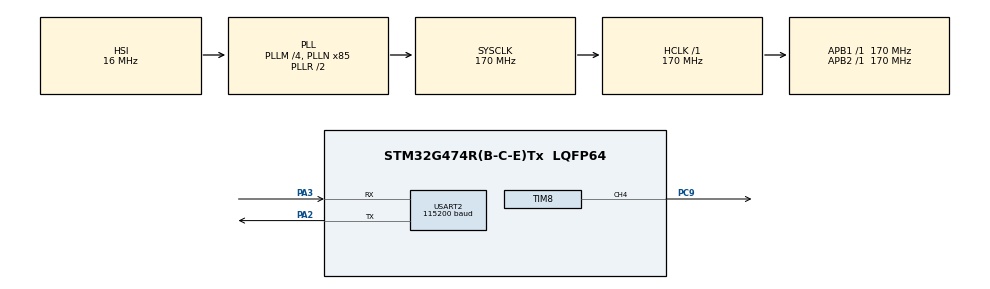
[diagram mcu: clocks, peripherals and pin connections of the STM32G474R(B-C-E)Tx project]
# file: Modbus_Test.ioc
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Dma.Request0=USART2_TX
Dma.USART2_TX.0.Direction=DMA_MEMORY_TO_PERIPH
Dma.USART2_TX.0.EventEnable=DISABLE
Dma.USART2_TX.0.Instance=DMA1_Channel1
Dma.USART2_TX.0.MemDataAlignment=DMA_MDATAALIGN_BYTE
Dma.USART2_TX.0.MemInc=DMA_MINC_ENABLE
Dma.USART2_TX.0.Mode=DMA_NORMAL
Dma.USART2_TX.0.PeriphDataAlignment=DMA_PDATAALIGN_BYTE
Dma.USART2_TX.0.PeriphInc=DMA_PINC_DISABLE
Dma.USART2_TX.0.Polarity=HAL_DMAMUX_REQ_GEN_RISING
Dma.USART2_TX.0.Priority=DMA_PRIORITY_LOW
Dma.USART2_TX.0.RequestNumber=1
Dma.USART2_TX.0.SignalID=NONE
Dma.USART2_TX.0.SyncEnable=DISABLE
Dma.USART2_TX.0.SyncPolarity=HAL_DMAMUX_SYNC_NO_EVENT
Dma.USART2_TX.0.SyncRequestNumber=1
Dma.USART2_TX.0.SyncSignalID=NONE
Mcu.Family=STM32G4
Mcu.Name=STM32G474R(B-C-E)Tx
Mcu.Package=LQFP64
NVIC.DMA1_Channel1_IRQn=true\:0\:0\:false\:false\:true\:false\:true\:true
NVIC.PriorityGroup=NVIC_PRIORITYGROUP_4
NVIC.TIM1_UP_TIM16_IRQn=true\:0\:0\:false\:false\:true\:true\:true\:true
NVIC.USART2_IRQn=true\:0\:0\:false\:false\:true\:true\:true\:true
PA13.GPIO_Label=T_SWDIO
PA13.Signal=SYS_JTMS-SWDIO
PA14.GPIO_Label=T_SWCLK
PA14.Signal=SYS_JTCK-SWCLK
PA2.Mode=Asynchronous
PA2.Signal=USART2_TX
PA3.Mode=Asynchronous
PA3.Signal=USART2_RX
PB3.GPIO_Label=T_SWO
PB3.Signal=SYS_JTDO-SWO
PC14-OSC32_IN.GPIO_Label=RCC_OSC32_IN
PC14-OSC32_IN.Signal=RCC_OSC32_IN
PC15-OSC32_OUT.GPIO_Label=RCC_OSC32_OUT
PC15-OSC32_OUT.Signal=RCC_OSC32_OUT
PC9.Signal=S_TIM8_CH4
PF0-OSC_IN.GPIO_Label=RCC_OSC_IN
PF0-OSC_IN.Signal=RCC_OSC_IN
PF1-OSC_OUT.GPIO_Label=RCC_OSC_OUT
PF1-OSC_OUT.Signal=RCC_OSC_OUT
ProjectManager.HeapSize=0x200
ProjectManager.StackSize=0x400
ProjectManager.TargetToolchain=STM32CubeIDE
RCC.ADC12Freq_Value=170000000
RCC.ADC345Freq_Value=170000000
RCC.AHBFreq_Value=170000000
RCC.APB1Freq_Value=170000000
RCC.APB1TimFreq_Value=170000000
RCC.APB2Freq_Value=170000000
RCC.APB2TimFreq_Value=170000000
RCC.CortexFreq_Value=170000000
RCC.EXTERNAL_CLOCK_VALUE=12288000
RCC.HCLKFreq_Value=170000000
RCC.HSE_VALUE=24000000
RCC.HSI48_VALUE=48000000
RCC.HSI_VALUE=16000000
RCC.LSE_VALUE=32768
RCC.PLLM=RCC_PLLM_DIV4
RCC.PLLN=85
RCC.RTCClockSelection=RCC_RTCCLKSOURCE_LSE
RCC.SYSCLKFreq_VALUE=170000000
RCC.SYSCLKSource=RCC_SYSCLKSOURCE_PLLCLK
RCC.USBFreq_Value=170000000
RCC.VCOOutputFreq_Value=340000000
SH.S_TIM8_CH4.0=TIM8_CH4,PWM Generation4 CH4
TIM16.Channel=TIM_CHANNEL_1
TIM16.OCMode_1=TIM_OCMODE_ACTIVE
TIM16.PeriodNoDither=335
TIM16.Prescaler=169
TIM16.PulseNoDither_1=239
TIM8.Channel-PWM\ Generation4\ CH4=TIM_CHANNEL_4
USART2.BaudRate=115200
USART2.Parity=PARITY_EVEN
USART2.VirtualMode-Asynchronous=VM_ASYNC
USART2.WordLength=WORDLENGTH_9B
VP_SYS_VS_DBSignals.Mode=DisableDeadBatterySignals
VP_TIM16_VS_ClockSourceINT.Mode=Enable_Timer
VP_TIM16_VS_OPM.Mode=OPM_bit
VP_TIM16_VS_no_output1.Mode=Output Compare1 No Output
VP_TIM8_VS_ClockSourceINT.Mode=Internal
board=NUCLEO-G474RE

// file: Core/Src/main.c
/* USER CODE BEGIN Header */
/**
  ******************************************************************************
  * @file           : main.c
  * @brief          : Main program body
  ******************************************************************************
  * @attention
  *
  * Copyright (c) 2025 STMicroelectronics.
  * All rights reserved.
  *
  * This software is licensed under terms that can be found in the LICENSE file
  * in the root directory of this software component.
  * If no LICENSE file comes with this software, it is provided AS-IS.
  *
  ******************************************************************************
  */
/* USER CODE END Header */
#include "main.h"

/* USER CODE BEGIN Includes */
#include "ModBusRTU.h"
/* USER CODE END Includes */

TIM_HandleTypeDef htim8;
TIM_HandleTypeDef htim16;

UART_HandleTypeDef huart2;
DMA_HandleTypeDef hdma_usart2_tx;

/* USER CODE BEGIN PV */
ModbusHandleTypedef hmodbus;
u16u8_t registerFrame[200];
float R_goal;
float theta_goal;
uint8_t status_Base ;
uint8_t status_moving ;
uint8_t A ;
/* USER CODE END PV */

void SystemClock_Config(void);
static void MX_GPIO_Init(void);
static void MX_DMA_Init(void);
static void MX_TIM16_Init(void);
static void MX_USART2_UART_Init(void);
static void MX_TIM8_Init(void);

int main(void)
{

  /* MCU Configuration--------------------------------------------------------*/

  /* Reset of all peripherals, Initializes the Flash interface and the Systick. */
  HAL_Init();

  /* Configure the system clock */
  SystemClock_Config();

  /* Initialize all configured peripherals */
  MX_GPIO_Init();
  MX_DMA_Init();
  MX_TIM16_Init();
  MX_USART2_UART_Init();
  MX_TIM8_Init();
  /* USER CODE BEGIN 2 */
  hmodbus.huart = &huart2;
  hmodbus.htim = &htim16;
  hmodbus.slaveAddress = 0x15;
  hmodbus.RegisterSize =200;
  Modbus_init(&hmodbus, registerFrame);
  /* USER CODE END 2 */

  /* Infinite loop */
  while (1)
  {

    /* USER CODE BEGIN 3 */
	  Modbus_Protocal_Worker();
	  R_goal =modbus_set_goal_r_position(&hmodbus);
	  theta_goal =modbus_set_goal_theta_position(&hmodbus);
	  status_Base = modbus_Base_System_Status(&hmodbus);
	  status_moving =R_Theta_moving_Status(&hmodbus,A);
	  registerFrame[0x00].U16 = 22881;
	  registerFrame[0x15].U16 = 100;
  }
  /* USER CODE END 3 */
}

void SystemClock_Config(void)
{
  RCC_OscInitTypeDef RCC_OscInitStruct = {0};
  RCC_ClkInitTypeDef RCC_ClkInitStruct = {0};

  /** Configure the main internal regulator output voltage
  */
  HAL_PWREx_ControlVoltageScaling(PWR_REGULATOR_VOLTAGE_SCALE1_BOOST);

  /** Initializes the RCC Oscillators according to the specified parameters
  * in the RCC_OscInitTypeDef structure.
  */
  RCC_OscInitStruct.OscillatorType = RCC_OSCILLATORTYPE_HSI;
  RCC_OscInitStruct.HSIState = RCC_HSI_ON;
  RCC_OscInitStruct.HSICalibrationValue = RCC_HSICALIBRATION_DEFAULT;
  RCC_OscInitStruct.PLL.PLLState = RCC_PLL_ON;
  RCC_OscInitStruct.PLL.PLLSource = RCC_PLLSOURCE_HSI;
  RCC_OscInitStruct.PLL.PLLM = RCC_PLLM_DIV4;
  RCC_OscInitStruct.PLL.PLLN = 85;
  RCC_OscInitStruct.PLL.PLLP = RCC_PLLP_DIV2;
  RCC_OscInitStruct.PLL.PLLQ = RCC_PLLQ_DIV2;
  RCC_OscInitStruct.PLL.PLLR = RCC_PLLR_DIV2;
  if (HAL_RCC_OscConfig(&RCC_OscInitStruct) != HAL_OK)
  {
    Error_Handler();
  }

  /** Initializes the CPU, AHB and APB buses clocks
  */
  RCC_ClkInitStruct.ClockType = RCC_CLOCKTYPE_HCLK|RCC_CLOCKTYPE_SYSCLK
                              |RCC_CLOCKTYPE_PCLK1|RCC_CLOCKTYPE_PCLK2;
  RCC_ClkInitStruct.SYSCLKSource = RCC_SYSCLKSOURCE_PLLCLK;
  RCC_ClkInitStruct.AHBCLKDivider = RCC_SYSCLK_DIV1;
  RCC_ClkInitStruct.APB1CLKDivider = RCC_HCLK_DIV1;
  RCC_ClkInitStruct.APB2CLKDivider = RCC_HCLK_DIV1;

  if (HAL_RCC_ClockConfig(&RCC_ClkInitStruct, FLASH_LATENCY_4) != HAL_OK)
  {
    Error_Handler();
  }
}

static void MX_TIM8_Init(void)
{

  TIM_ClockConfigTypeDef sClockSourceConfig = {0};
  TIM_MasterConfigTypeDef sMasterConfig = {0};
  TIM_OC_InitTypeDef sConfigOC = {0};
  TIM_BreakDeadTimeConfigTypeDef sBreakDeadTimeConfig = {0};

  htim8.Instance = TIM8;
  htim8.Init.Prescaler = 0;
  htim8.Init.CounterMode = TIM_COUNTERMODE_UP;
  htim8.Init.Period = 65535;
  htim8.Init.ClockDivision = TIM_CLOCKDIVISION_DIV1;
  htim8.Init.RepetitionCounter = 0;
  htim8.Init.AutoReloadPreload = TIM_AUTORELOAD_PRELOAD_DISABLE;
  if (HAL_TIM_Base_Init(&htim8) != HAL_OK)
  {
    Error_Handler();
  }
  sClockSourceConfig.ClockSource = TIM_CLOCKSOURCE_INTERNAL;
  if (HAL_TIM_ConfigClockSource(&htim8, &sClockSourceConfig) != HAL_OK)
  {
    Error_Handler();
  }
  if (HAL_TIM_PWM_Init(&htim8) != HAL_OK)
  {
    Error_Handler();
  }
  sMasterConfig.MasterOutputTrigger = TIM_TRGO_RESET;
  sMasterConfig.MasterOutputTrigger2 = TIM_TRGO2_RESET;
  sMasterConfig.MasterSlaveMode = TIM_MASTERSLAVEMODE_DISABLE;
  if (HAL_TIMEx_MasterConfigSynchronization(&htim8, &sMasterConfig) != HAL_OK)
  {
    Error_Handler();
  }
  sConfigOC.OCMode = TIM_OCMODE_PWM1;
  sConfigOC.Pulse = 0;
  sConfigOC.OCPolarity = TIM_OCPOLARITY_HIGH;
  sConfigOC.OCNPolarity = TIM_OCNPOLARITY_HIGH;
  sConfigOC.OCFastMode = TIM_OCFAST_DISABLE;
  sConfigOC.OCIdleState = TIM_OCIDLESTATE_RESET;
  sConfigOC.OCNIdleState = TIM_OCNIDLESTATE_RESET;
  if (HAL_TIM_PWM_ConfigChannel(&htim8, &sConfigOC, TIM_CHANNEL_4) != HAL_OK)
  {
    Error_Handler();
  }
  sBreakDeadTimeConfig.OffStateRunMode = TIM_OSSR_DISABLE;
  sBreakDeadTimeConfig.OffStateIDLEMode = TIM_OSSI_DISABLE;
  sBreakDeadTimeConfig.LockLevel = TIM_LOCKLEVEL_OFF;
  sBreakDeadTimeConfig.DeadTime = 0;
  sBreakDeadTimeConfig.BreakState = TIM_BREAK_DISABLE;
  sBreakDeadTimeConfig.BreakPolarity = TIM_BREAKPOLARITY_HIGH;
  sBreakDeadTimeConfig.BreakFilter = 0;
  sBreakDeadTimeConfig.BreakAFMode = TIM_BREAK_AFMODE_INPUT;
  sBreakDeadTimeConfig.Break2State = TIM_BREAK2_DISABLE;
  sBreakDeadTimeConfig.Break2Polarity = TIM_BREAK2POLARITY_HIGH;
  sBreakDeadTimeConfig.Break2Filter = 0;
  sBreakDeadTimeConfig.Break2AFMode = TIM_BREAK_AFMODE_INPUT;
  sBreakDeadTimeConfig.AutomaticOutput = TIM_AUTOMATICOUTPUT_DISABLE;
  if (HAL_TIMEx_ConfigBreakDeadTime(&htim8, &sBreakDeadTimeConfig) != HAL_OK)
  {
    Error_Handler();
  }
  HAL_TIM_MspPostInit(&htim8);

}

static void MX_TIM16_Init(void)
{

  TIM_OC_InitTypeDef sConfigOC = {0};
  TIM_BreakDeadTimeConfigTypeDef sBreakDeadTimeConfig = {0};

  htim16.Instance = TIM16;
  htim16.Init.Prescaler = 169;
  htim16.Init.CounterMode = TIM_COUNTERMODE_UP;
  htim16.Init.Period = 335;
  htim16.Init.ClockDivision = TIM_CLOCKDIVISION_DIV1;
  htim16.Init.RepetitionCounter = 0;
  htim16.Init.AutoReloadPreload = TIM_AUTORELOAD_PRELOAD_DISABLE;
  if (HAL_TIM_Base_Init(&htim16) != HAL_OK)
  {
    Error_Handler();
  }
  if (HAL_TIM_OC_Init(&htim16) != HAL_OK)
  {
    Error_Handler();
  }
  if (HAL_TIM_OnePulse_Init(&htim16, TIM_OPMODE_SINGLE) != HAL_OK)
  {
    Error_Handler();
  }
  sConfigOC.OCMode = TIM_OCMODE_ACTIVE;
  sConfigOC.Pulse = 239;
  sConfigOC.OCPolarity = TIM_OCPOLARITY_HIGH;
  sConfigOC.OCNPolarity = TIM_OCNPOLARITY_HIGH;
  sConfigOC.OCFastMode = TIM_OCFAST_DISABLE;
  sConfigOC.OCIdleState = TIM_OCIDLESTATE_RESET;
  sConfigOC.OCNIdleState = TIM_OCNIDLESTATE_RESET;
  if (HAL_TIM_OC_ConfigChannel(&htim16, &sConfigOC, TIM_CHANNEL_1) != HAL_OK)
  {
    Error_Handler();
  }
  sBreakDeadTimeConfig.OffStateRunMode = TIM_OSSR_DISABLE;
  sBreakDeadTimeConfig.OffStateIDLEMode = TIM_OSSI_DISABLE;
  sBreakDeadTimeConfig.LockLevel = TIM_LOCKLEVEL_OFF;
  sBreakDeadTimeConfig.DeadTime = 0;
  sBreakDeadTimeConfig.BreakState = TIM_BREAK_DISABLE;
  sBreakDeadTimeConfig.BreakPolarity = TIM_BREAKPOLARITY_HIGH;
  sBreakDeadTimeConfig.BreakFilter = 0;
  sBreakDeadTimeConfig.AutomaticOutput = TIM_AUTOMATICOUTPUT_DISABLE;
  if (HAL_TIMEx_ConfigBreakDeadTime(&htim16, &sBreakDeadTimeConfig) != HAL_OK)
  {
    Error_Handler();
  }

}

static void MX_USART2_UART_Init(void)
{

  huart2.Instance = USART2;
  huart2.Init.BaudRate = 115200;
  huart2.Init.WordLength = UART_WORDLENGTH_9B;
  huart2.Init.StopBits = UART_STOPBITS_1;
  huart2.Init.Parity = UART_PARITY_EVEN;
  huart2.Init.Mode = UART_MODE_TX_RX;
  huart2.Init.HwFlowCtl = UART_HWCONTROL_NONE;
  huart2.Init.OverSampling = UART_OVERSAMPLING_16;
  huart2.Init.OneBitSampling = UART_ONE_BIT_SAMPLE_DISABLE;
  huart2.Init.ClockPrescaler = UART_PRESCALER_DIV1;
  huart2.AdvancedInit.AdvFeatureInit = UART_ADVFEATURE_NO_INIT;
  if (HAL_UART_Init(&huart2) != HAL_OK)
  {
    Error_Handler();
  }
  if (HAL_UARTEx_SetTxFifoThreshold(&huart2, UART_TXFIFO_THRESHOLD_1_8) != HAL_OK)
  {
    Error_Handler();
  }
  if (HAL_UARTEx_SetRxFifoThreshold(&huart2, UART_RXFIFO_THRESHOLD_1_8) != HAL_OK)
  {
    Error_Handler();
  }
  if (HAL_UARTEx_DisableFifoMode(&huart2) != HAL_OK)
  {
    Error_Handler();
  }

}

static void MX_DMA_Init(void)
{

  /* DMA controller clock enable */
  __HAL_RCC_DMAMUX1_CLK_ENABLE();
  __HAL_RCC_DMA1_CLK_ENABLE();

  /* DMA interrupt init */
  /* DMA1_Channel1_IRQn interrupt configuration */
  HAL_NVIC_SetPriority(DMA1_Channel1_IRQn, 0, 0);
  HAL_NVIC_EnableIRQ(DMA1_Channel1_IRQn);

}

static void MX_GPIO_Init(void)
{

  /* GPIO Ports Clock Enable */
  __HAL_RCC_GPIOC_CLK_ENABLE();
  __HAL_RCC_GPIOF_CLK_ENABLE();
  __HAL_RCC_GPIOA_CLK_ENABLE();
  __HAL_RCC_GPIOB_CLK_ENABLE();

}

void Error_Handler(void)
{
  __disable_irq();
  while (1)
  {
  }
}
